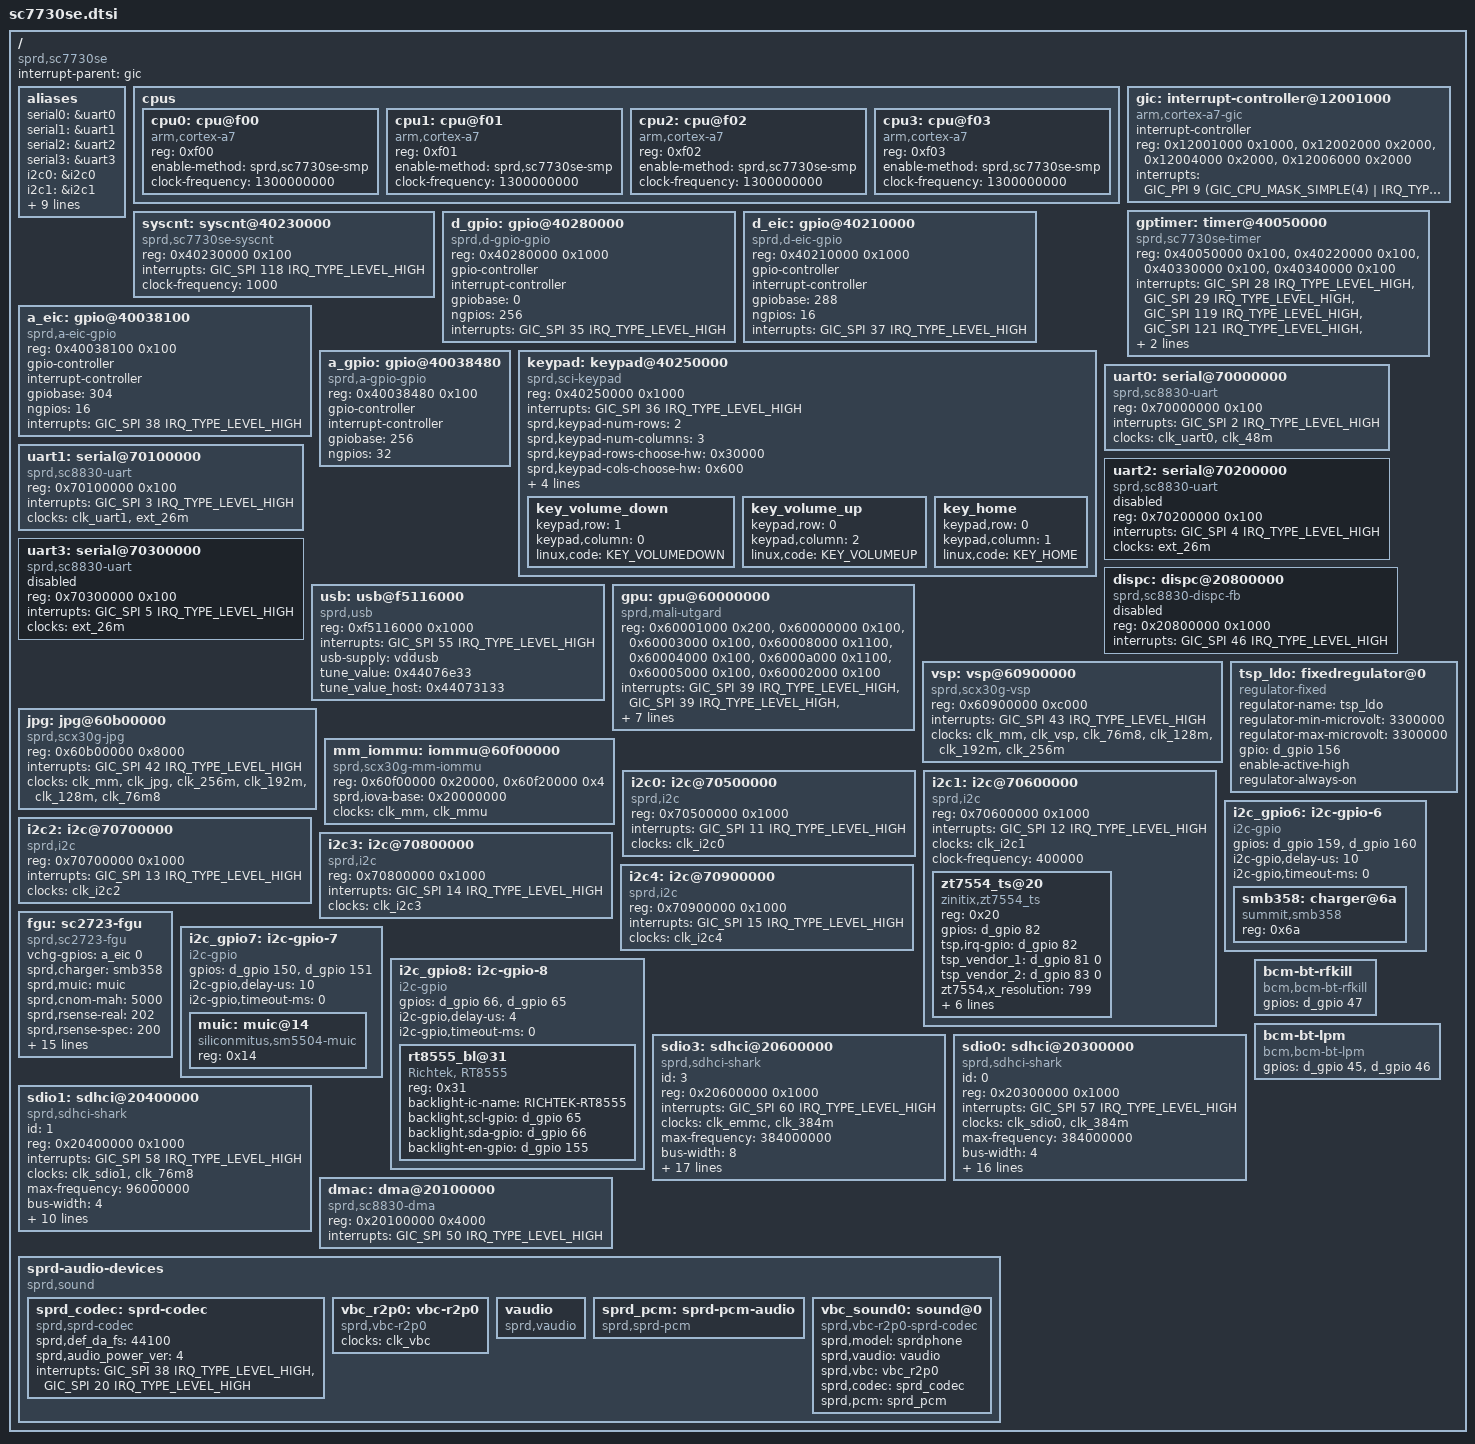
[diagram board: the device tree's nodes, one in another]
/*
 * Spreadtrum SC7730SE SoC Device Tree Include (SCX30G / SCX35 TShark2)
 *
 * Hardware map verified 1:1 against Samsung SM-T560 / SM-T561 3.10 kernel source
 * (sprd-scx35.dtsi, sprd-scx35_sc7730.dtsi, sprd-scx35_gtelwifi_rev11.dts,
 *  and sprd-scx35_gtel3g_rev11.dts).
 *
 * Peripherals are placed directly under '/' (matching sprd-scx35.dtsi) so
 * platform device sysfs paths (/devices/platform/sprd-sdhci.3) match Android's
 * fstab.sc8830 (/dev/block/platform/sprd-sdhci.3/by-name/SYSTEM).
 *
 * Licensed under the GPL-2.
 */

#include <dt-bindings/interrupt-controller/arm-gic.h>
#include <dt-bindings/interrupt-controller/irq.h>
#include <dt-bindings/gpio/gpio.h>
#include <dt-bindings/input/input.h>

#include "scx30g-clocks.dtsi"
#include "sc2723-regulators.dtsi"

/ {
	#address-cells = <1>;
	#size-cells = <1>;
	compatible = "sprd,sc7730se", "sprd,sc8830", "sprd,sp8830", "sprd,scx35";
	interrupt-parent = <&gic>;

	aliases {
		serial0 = &uart0;
		serial1 = &uart1;
		serial2 = &uart2;
		serial3 = &uart3;
		i2c0 = &i2c0;
		i2c1 = &i2c1;
		i2c2 = &i2c2;
		i2c3 = &i2c3;
		i2c4 = &i2c4;
		i2c6 = &i2c_gpio6;
		i2c7 = &i2c_gpio7;
		i2c8 = &i2c_gpio8;
		mmc0 = &sdio3;
		mmc1 = &sdio0;
		mmc2 = &sdio1;
	};

	cpus {
		#address-cells = <1>;
		#size-cells = <0>;

		cpu0: cpu@f00 {
			device_type = "cpu";
			compatible = "arm,cortex-a7";
			reg = <0xf00>;
			enable-method = "sprd,sc7730se-smp";
			clock-frequency = <1300000000>;
		};

		cpu1: cpu@f01 {
			device_type = "cpu";
			compatible = "arm,cortex-a7";
			reg = <0xf01>;
			enable-method = "sprd,sc7730se-smp";
			clock-frequency = <1300000000>;
		};

		cpu2: cpu@f02 {
			device_type = "cpu";
			compatible = "arm,cortex-a7";
			reg = <0xf02>;
			enable-method = "sprd,sc7730se-smp";
			clock-frequency = <1300000000>;
		};

		cpu3: cpu@f03 {
			device_type = "cpu";
			compatible = "arm,cortex-a7";
			reg = <0xf03>;
			enable-method = "sprd,sc7730se-smp";
			clock-frequency = <1300000000>;
		};
	};

	/*
	 * GIC-400 (Cortex-A7 MPCore has NO SCU MMIO block at 0x12000000!)
	 */
	gic: interrupt-controller@12001000 {
		compatible = "arm,cortex-a7-gic", "arm,cortex-a15-gic";
		#interrupt-cells = <3>;
		interrupt-controller;
		reg = <0x12001000 0x1000>,
		      <0x12002000 0x2000>,
		      <0x12004000 0x2000>,
		      <0x12006000 0x2000>;
		interrupts = <GIC_PPI 9 (GIC_CPU_MASK_SIMPLE(4) | IRQ_TYPE_LEVEL_HIGH)>;
	};

	/*
	 * Spreadtrum GPTIMERs (AON_TMR + AP_TMR0..2):
	 * - 0x40050000 (AON_TMR): CPU0 local timer (SPI 28) + 32768 Hz clocksource
	 * - 0x40220000 (AP_TMR0): CPU1 local timer (SPI 29) + bctimer (SPI 118)
	 * - 0x40330000 (AP_TMR1): CPU2 local timer (SPI 119)
	 * - 0x40340000 (AP_TMR2): CPU3 local timer (SPI 121)
	 */
	gptimer: timer@40050000 {
		compatible = "sprd,sc7730se-timer", "sprd,sc8830-timer", "sprd,scx35-timer";
		reg = <0x40050000 0x100>,
		      <0x40220000 0x100>,
		      <0x40330000 0x100>,
		      <0x40340000 0x100>;
		interrupts = <GIC_SPI 28 IRQ_TYPE_LEVEL_HIGH>,
			     <GIC_SPI 29 IRQ_TYPE_LEVEL_HIGH>,
			     <GIC_SPI 119 IRQ_TYPE_LEVEL_HIGH>,
			     <GIC_SPI 121 IRQ_TYPE_LEVEL_HIGH>,
			     <GIC_SPI 118 IRQ_TYPE_LEVEL_HIGH>;
		clock-frequency = <32768>;
	};

	/*
	 * Spreadtrum SYSCNT (0x40230000): 1000 Hz millisecond counter
	 */
	syscnt: syscnt@40230000 {
		compatible = "sprd,sc7730se-syscnt", "sprd,sc8830-syscnt";
		reg = <0x40230000 0x100>;
		interrupts = <GIC_SPI 118 IRQ_TYPE_LEVEL_HIGH>;
		clock-frequency = <1000>;
	};

	/*
	 * D-Die & A-Die GPIO and EIC Controllers (matching sprd-scx35.dtsi)
	 * - d_gpio: base 0, ngpios 256, GIC_SPI 35
	 * - a_gpio: base 256, ngpios 32
	 * - d_eic:  base 288, ngpios 16, GIC_SPI 37
	 * - a_eic:  base 304, ngpios 16, GIC_SPI 38 (ANA_INT)
	 */
	d_gpio: gpio@40280000 {
		compatible = "sprd,d-gpio-gpio";
		reg = <0x40280000 0x1000>;
		gpio-controller;
		#gpio-cells = <2>;
		interrupt-controller;
		#interrupt-cells = <2>;
		gpiobase = <0>;
		ngpios = <256>;
		interrupts = <GIC_SPI 35 IRQ_TYPE_LEVEL_HIGH>;
	};

	d_eic: gpio@40210000 {
		compatible = "sprd,d-eic-gpio";
		reg = <0x40210000 0x1000>;
		gpio-controller;
		#gpio-cells = <2>;
		interrupt-controller;
		#interrupt-cells = <2>;
		gpiobase = <288>;
		ngpios = <16>;
		interrupts = <GIC_SPI 37 IRQ_TYPE_LEVEL_HIGH>;
	};

	a_eic: gpio@40038100 {
		compatible = "sprd,a-eic-gpio";
		reg = <0x40038100 0x100>;
		gpio-controller;
		#gpio-cells = <2>;
		interrupt-controller;
		#interrupt-cells = <2>;
		gpiobase = <304>;
		ngpios = <16>;
		interrupts = <GIC_SPI 38 IRQ_TYPE_LEVEL_HIGH>;
	};

	a_gpio: gpio@40038480 {
		compatible = "sprd,a-gpio-gpio";
		reg = <0x40038480 0x100>;
		gpio-controller;
		#gpio-cells = <2>;
		interrupt-controller;
		#interrupt-cells = <2>;
		gpiobase = <256>;
		ngpios = <32>;
	};

	/*
	 * Spreadtrum Keypad Controller (0x40250000, GIC_SPI 36)
	 * Matching sprd-scx35_gtelwifi_rev11.dts / sprd-scx35_gtel3g_rev11.dts
	 */
	keypad: keypad@40250000 {
		compatible = "sprd,sci-keypad";
		reg = <0x40250000 0x1000>;
		interrupts = <GIC_SPI 36 IRQ_TYPE_LEVEL_HIGH>;
		sprd,keypad-num-rows = <2>;
		sprd,keypad-num-columns = <3>;
		sprd,keypad-rows-choose-hw = <0x30000>;
		sprd,keypad-cols-choose-hw = <0x600>;
		sprd,debounce_time = <5000>;
		linux,input-no-autorepeat;
		linux,input-wakeup;
		gpios = <&a_eic 2 0>, <&a_eic 10 0>;

		key_volume_down {
			keypad,row = <1>;
			keypad,column = <0>;
			linux,code = <KEY_VOLUMEDOWN>;
		};

		key_volume_up {
			keypad,row = <0>;
			keypad,column = <2>;
			linux,code = <KEY_VOLUMEUP>;
		};

		key_home {
			keypad,row = <0>;
			keypad,column = <1>;
			linux,code = <KEY_HOME>;
		};
	};

	/*
	 * Spreadtrum UARTs (0x70000000..0x70300000)
	 * uart0 is the Bluetooth HCI UART running at 48 MHz (3 Mbps baud).
	 */
	uart0: serial@70000000 {
		compatible = "sprd,sc8830-uart";
		reg = <0x70000000 0x100>;
		interrupts = <GIC_SPI 2 IRQ_TYPE_LEVEL_HIGH>;
		clocks = <&clk_uart0>, <&clk_48m>;
		status = "okay";
	};

	uart1: serial@70100000 {
		compatible = "sprd,sc8830-uart";
		reg = <0x70100000 0x100>;
		interrupts = <GIC_SPI 3 IRQ_TYPE_LEVEL_HIGH>;
		clocks = <&clk_uart1>, <&ext_26m>;
		status = "okay";
	};

	uart2: serial@70200000 {
		compatible = "sprd,sc8830-uart";
		reg = <0x70200000 0x100>;
		interrupts = <GIC_SPI 4 IRQ_TYPE_LEVEL_HIGH>;
		clocks = <&ext_26m>;
		status = "disabled";
	};

	uart3: serial@70300000 {
		compatible = "sprd,sc8830-uart";
		reg = <0x70300000 0x100>;
		interrupts = <GIC_SPI 5 IRQ_TYPE_LEVEL_HIGH>;
		clocks = <&ext_26m>;
		status = "disabled";
	};

	/*
	 * Mali-400 MP2 (Utgard r4p1).  All GP/PP/MMU interrupts share SPI 39.
	 * Register order/names follow the stock DT; the driver matches cores
	 * by address.
	 */
	/* Display controller (DISPC0), set up by the bootloader */
	dispc: dispc@20800000 {
		compatible = "sprd,sc8830-dispc-fb";
		reg = <0x20800000 0x1000>;
		interrupts = <GIC_SPI 46 IRQ_TYPE_LEVEL_HIGH>;
		status = "disabled";
	};

	/* DWC_otg 2.93a High-Speed USB 2.0 OTG Controller (0x20200000 mapped at 0xf5116000) */
	usb: usb@f5116000 {
		compatible = "sprd,usb";
		reg = <0xf5116000 0x1000>;
		interrupts = <GIC_SPI 55 IRQ_TYPE_LEVEL_HIGH>;
		usb-supply = <&vddusb>;
		tune_value = <0x44076e33>;
		tune_value_host = <0x44073133>;
		status = "okay";
	};

	gpu: gpu@60000000 {
		compatible = "sprd,mali-utgard";
		reg = <0x60001000 0x200>, <0x60000000 0x100>, <0x60003000 0x100>,
		      <0x60008000 0x1100>, <0x60004000 0x100>, <0x6000a000 0x1100>,
		      <0x60005000 0x100>, <0x60002000 0x100>;
		reg-names = "mali_l2", "mali_gp", "mali_gp_mmu", "mali_pp0",
			    "mali_pp0_mmu", "mali_pp1", "mali_pp1_mmu", "mali_pmu";
		interrupts = <GIC_SPI 39 IRQ_TYPE_LEVEL_HIGH>,
			     <GIC_SPI 39 IRQ_TYPE_LEVEL_HIGH>,
			     <GIC_SPI 39 IRQ_TYPE_LEVEL_HIGH>,
			     <GIC_SPI 39 IRQ_TYPE_LEVEL_HIGH>,
			     <GIC_SPI 39 IRQ_TYPE_LEVEL_HIGH>,
			     <GIC_SPI 39 IRQ_TYPE_LEVEL_HIGH>;
		interrupt-names = "mali_gp_irq", "mali_gp_mmu_irq",
				  "mali_pp0_irq", "mali_pp0_mmu_irq",
				  "mali_pp1_irq", "mali_pp1_mmu_irq";
		/* gpu_axi, then the clk_gpu mux inputs used for DVFS */
		clocks = <&clk_gpu_axi>, <&clk_384m>, <&clk_460m8>, <&clk_312m>,
			 <&clk_256m>, <&clk_153m6>;
		clock-names = "clk_gpu_axi", "clk_384m", "clk_460m8",
			      "clk_312m", "clk_256m", "clk_153m6";
		mali_pp_core_number = <2>;
	};

	/*
	 * Video (VSP) and JPEG codecs in the MM power domain, driven from
	 * userspace (OMX, camera HAL) through /dev/sprd_vsp and /dev/sprd_jpg.
	 * "levelN" is the codec clock input that frequency level N of the
	 * vendor ioctl ABI selects: mux order for the VSP, fastest first for
	 * the JPEG codec, as in the 3.10 drivers.
	 */
	vsp: vsp@60900000 {
		compatible = "sprd,scx30g-vsp";
		reg = <0x60900000 0xc000>;
		interrupts = <GIC_SPI 43 IRQ_TYPE_LEVEL_HIGH>;
		clocks = <&clk_mm>, <&clk_vsp>, <&clk_76m8>, <&clk_128m>,
			 <&clk_192m>, <&clk_256m>;
		clock-names = "clk_mm_i", "clk_vsp", "level0", "level1",
			      "level2", "level3";
	};

	jpg: jpg@60b00000 {
		compatible = "sprd,scx30g-jpg";
		reg = <0x60b00000 0x8000>;
		interrupts = <GIC_SPI 42 IRQ_TYPE_LEVEL_HIGH>;
		clocks = <&clk_mm>, <&clk_jpg>, <&clk_256m>, <&clk_192m>,
			 <&clk_128m>, <&clk_76m8>;
		clock-names = "clk_mm_i", "clk_jpg", "level0", "level1",
			      "level2", "level3";
	};

	/*
	 * IOMMU of the MM masters: page table SRAM (one entry per 4 KiB of
	 * the window) and control register, as on 3.10.
	 */
	mm_iommu: iommu@60f00000 {
		compatible = "sprd,scx30g-mm-iommu";
		reg = <0x60f00000 0x20000>, <0x60f20000 0x4>;
		reg-names = "pgt", "ctrl";
		sprd,iova-base = <0x20000000>;
		clocks = <&clk_mm>, <&clk_mmu>;
		clock-names = "clk_mm_i", "clk_mmu";
	};

	/*
	 * Zinitix ZT7554 3.3V LDO regulator (GPIO 156 active-high)
	 */
	tsp_ldo: fixedregulator@0 {
		compatible = "regulator-fixed";
		regulator-name = "tsp_ldo";
		regulator-min-microvolt = <3300000>;
		regulator-max-microvolt = <3300000>;
		gpio = <&d_gpio 156 0>;
		enable-active-high;
		regulator-always-on;
	};

	/*
	 * Spreadtrum Hardware I2C Controllers (0x70500000..0x70900000)
	 */
	i2c0: i2c@70500000 {
		compatible = "sprd,i2c", "sprd,sp8830-i2c";
		reg = <0x70500000 0x1000>;
		interrupts = <GIC_SPI 11 IRQ_TYPE_LEVEL_HIGH>;
		clocks = <&clk_i2c0>;
		#address-cells = <1>;
		#size-cells = <0>;
		status = "okay";
	};

	i2c1: i2c@70600000 {
		compatible = "sprd,i2c", "sprd,sp8830-i2c";
		reg = <0x70600000 0x1000>;
		interrupts = <GIC_SPI 12 IRQ_TYPE_LEVEL_HIGH>;
		clocks = <&clk_i2c1>;
		clock-frequency = <400000>;
		#address-cells = <1>;
		#size-cells = <0>;
		status = "okay";

		zt7554_ts@20 {
			compatible = "zinitix,zt7554_ts";
			reg = <0x20>;
			gpios = <&d_gpio 82 0>;
			tsp,irq-gpio = <&d_gpio 82 0>;
			tsp_vendor_1 = <&d_gpio 81 0>;
			tsp_vendor_2 = <&d_gpio 83 0>;
			zt7554,x_resolution = <799>;
			zt7554,y_resolution = <1279>;
			tsp,x_resolution = <800>;
			tsp,y_resolution = <1280>;
			tsp_vdd-supply = <&tsp_ldo>;
			zt7554,core_num = <4>;
			zt7554,model_name = "T560";
		};
	};

	i2c2: i2c@70700000 {
		compatible = "sprd,i2c", "sprd,sp8830-i2c";
		reg = <0x70700000 0x1000>;
		interrupts = <GIC_SPI 13 IRQ_TYPE_LEVEL_HIGH>;
		clocks = <&clk_i2c2>;
		#address-cells = <1>;
		#size-cells = <0>;
		status = "okay";
	};

	i2c3: i2c@70800000 {
		compatible = "sprd,i2c", "sprd,sp8830-i2c";
		reg = <0x70800000 0x1000>;
		interrupts = <GIC_SPI 14 IRQ_TYPE_LEVEL_HIGH>;
		clocks = <&clk_i2c3>;
		#address-cells = <1>;
		#size-cells = <0>;
		status = "okay";
	};

	i2c4: i2c@70900000 {
		compatible = "sprd,i2c", "sprd,sp8830-i2c";
		reg = <0x70900000 0x1000>;
		interrupts = <GIC_SPI 15 IRQ_TYPE_LEVEL_HIGH>;
		clocks = <&clk_i2c4>;
		#address-cells = <1>;
		#size-cells = <0>;
		status = "okay";
	};

	/*
	 * Bit-banged GPIO I2C buses from sprd-scx35_gtelwifi_rev11.dts:
	 * - i2c_gpio6: SMB358 charger (SDA=GPIO159, SCL=GPIO160)
	 * - i2c_gpio7: SM5504 MUIC (SDA=GPIO150, SCL=GPIO151)
	 * - i2c_gpio8: Richtek RT8555 Backlight (SDA=GPIO66, SCL=GPIO65, EN=GPIO155)
	 */
	i2c_gpio6: i2c-gpio-6 {
		compatible = "i2c-gpio";
		gpios = <&d_gpio 159 0 /* sda */
			 &d_gpio 160 0 /* scl */>;
		i2c-gpio,delay-us = <10>;
		i2c-gpio,timeout-ms = <0>;
		#address-cells = <1>;
		#size-cells = <0>;
		status = "okay";

		/* set up by the SC2723 FGU driver for each charger attach */
		smb358: charger@6a {
			compatible = "summit,smb358";
			reg = <0x6a>;
		};
	};

	/*
	 * SC2723 fuel gauge. Battery data from the vendor 3.10
	 * sprd-scx35_gtelwifi/gtel3g DTs (5000 mAh pack, identical on all
	 * revisions); the NTC table is Samsung's sec_battery one.
	 */
	fgu: sc2723-fgu {
		compatible = "sprd,sc2723-fgu";
		vchg-gpios = <&a_eic 0 GPIO_ACTIVE_HIGH>;
		sprd,charger = <&smb358>;
		sprd,muic = <&muic>;
		sprd,cnom-mah = <5000>;
		sprd,rsense-real = <202>;
		sprd,rsense-spec = <200>;
		sprd,rint-mohm = <220>;
		sprd,relax-current-ma = <50>;
		sprd,alm-vbat-mv = <3500>;
		sprd,soft-uvlo-mv = <3050>;
		sprd,temp-adc-channel = <1>;
		/* OCV in mV, capacity in % */
		sprd,ocv-table = <4320 100>, <4262 95>, <4205 90>, <4152 85>,
				 <4101 80>, <4055 75>, <4006 70>, <3968 65>,
				 <3923 60>, <3880 55>, <3849 50>, <3824 45>,
				 <3806 40>, <3790 35>, <3778 30>, <3770 25>,
				 <3761 20>, <3744 15>, <3711 10>, <3690 5>,
				 <3400 0>;
		/* AUXADC raw value, temperature in 0.1 degC */
		sprd,temp-table = <653 700>, <889 600>, <963 580>, <1093 530>,
				  <1177 500>, <1307 460>, <1334 450>, <1549 400>,
				  <1940 300>, <2392 200>, <2727 100>, <2900 50>,
				  <3040 0>, <3210 (-50)>, <3360 (-100)>,
				  <3537 (-200)>;
		status = "okay";
	};

	i2c_gpio7: i2c-gpio-7 {
		compatible = "i2c-gpio";
		gpios = <&d_gpio 150 0 /* sda */
			 &d_gpio 151 0 /* scl */>;
		i2c-gpio,delay-us = <10>;
		i2c-gpio,timeout-ms = <0>;
		#address-cells = <1>;
		#size-cells = <0>;
		status = "okay";

		/* charger type, only read by the SC2723 FGU driver */
		muic: muic@14 {
			compatible = "siliconmitus,sm5504-muic";
			reg = <0x14>;
		};
	};

	i2c_gpio8: i2c-gpio-8 {
		compatible = "i2c-gpio";
		gpios = <&d_gpio 66 0 /* sda */
			 &d_gpio 65 0 /* scl */>;
		i2c-gpio,delay-us = <4>;
		i2c-gpio,timeout-ms = <0>;
		#address-cells = <1>;
		#size-cells = <0>;
		status = "okay";

		rt8555_bl@31 {
			compatible = "Richtek, RT8555";
			reg = <0x31>;
			backlight-ic-name = "RICHTEK-RT8555";
			backlight,scl-gpio = <&d_gpio 65 0>;
			backlight,sda-gpio = <&d_gpio 66 0>;
			backlight-en-gpio = <&d_gpio 155 GPIO_ACTIVE_HIGH>;
		};
	};

	/*
	 * Spreadtrum SDHCI Controllers (eMMC, SD, Wi-Fi SDIO)
	 * Placed directly under '/' so devpath is /devices/platform/sprd-sdhci.{0,1,3}
	 */
	sdio3: sdhci@20600000 {
		compatible = "sprd,sdhci-shark";
		id = <3>;
		reg = <0x20600000 0x1000>;
		interrupts = <GIC_SPI 60 IRQ_TYPE_LEVEL_HIGH>;
		clocks = <&clk_emmc>, <&clk_384m>;
		max-frequency = <384000000>;
		bus-width = <8>;
		enb-reg = <0x20d00000>;
		enb-bit = <0x800>;
		rst-reg = <0x20d00004>;
		rst-bit = <0x4000>;
		write-delay = <0x08>;
		read-pos-delay = <0x04>;
		read-neg-delay = <0x04>;
		host-caps-mask = <0x03000000>;
		sdhci-cap-1v8-ddr;
		sdhci-cap2-hc-erase-sz;
		sdhci-cap2-cache-ctrl;
		sdhci-cap2-poweroff-notify;
		sdhci-cap2-no-sleep-cmd;
		sdhci-cap2-power-always-on;
		non-removable;
		keep-power = <0>;
		runtime = <1>;
		status = "okay";
	};

	sdio0: sdhci@20300000 {
		compatible = "sprd,sdhci-shark";
		id = <0>;
		reg = <0x20300000 0x1000>;
		interrupts = <GIC_SPI 57 IRQ_TYPE_LEVEL_HIGH>;
		clocks = <&clk_sdio0>, <&clk_384m>;
		max-frequency = <384000000>;
		bus-width = <4>;
		enb-reg = <0x20d00000>;
		enb-bit = <0x100>;
		rst-reg = <0x20d00004>;
		rst-bit = <0x800>;
		write-delay = <0x08>;
		read-pos-delay = <0x08>;
		read-neg-delay = <0x08>;
		host-caps-mask = <0x05000000>;
		vdd-vmmc = "vddsdcore";
		vdd-vqmmc = "vddsdcore";
		vqmmc-voltage-level = <3000000>;
		cd-gpios = <&d_gpio 71 GPIO_ACTIVE_LOW>;
		sdhci-cap2-hc-erase-sz;
		sdhci-cap2-cache-ctrl;
		keep-power = <0>;
		runtime = <1>;
		status = "okay";
	};

	sdio1: sdhci@20400000 {
		compatible = "sprd,sdhci-shark";
		id = <1>;
		reg = <0x20400000 0x1000>;
		interrupts = <GIC_SPI 58 IRQ_TYPE_LEVEL_HIGH>;
		clocks = <&clk_sdio1>, <&clk_76m8>;
		max-frequency = <96000000>;
		bus-width = <4>;
		enb-reg = <0x20d00000>;
		enb-bit = <0x200>;
		rst-reg = <0x20d00004>;
		rst-bit = <0x1000>;
		write-delay = <0x03>;
		read-pos-delay = <0x05>;
		read-neg-delay = <0x05>;
		non-removable;
		keep-power = <1>;
		runtime = <1>;
		status = "okay";
	};

	bcm-bt-rfkill {
		compatible = "bcm,bcm-bt-rfkill";
		gpios = <&d_gpio 47 0>;
	};

	bcm-bt-lpm {
		compatible = "bcm,bcm-bt-lpm";
		gpios = <&d_gpio 45 0
			 &d_gpio 46 0>;
	};

	dmac: dma@20100000 {
		compatible = "sprd,sc8830-dma", "sprd,sprd-dma";
		reg = <0x20100000 0x4000>;
		interrupts = <GIC_SPI 50 IRQ_TYPE_LEVEL_HIGH>;
	};

	sprd-audio-devices {
		compatible = "sprd,sound", "simple-bus";
		#address-cells = <1>;
		#size-cells = <1>;

		sprd_codec: sprd-codec {
			compatible = "sprd,sprd-codec";
			status = "okay";
			sprd,def_da_fs = <44100>;
			sprd,audio_power_ver = <4>;
			interrupts = <GIC_SPI 38 IRQ_TYPE_LEVEL_HIGH>,
				     <GIC_SPI 20 IRQ_TYPE_LEVEL_HIGH>;
		};

		vbc_r2p0: vbc-r2p0 {
			compatible = "sprd,vbc-r2p0";
			clocks = <&clk_vbc>;
			clock-names = "clk_vbc";
			status = "okay";
		};

		vaudio: vaudio {
			compatible = "sprd,vaudio";
			status = "okay";
		};

		sprd_pcm: sprd-pcm-audio {
			compatible = "sprd,sprd-pcm";
			status = "okay";
		};

		vbc_sound0: sound@0 {
			compatible = "sprd,vbc-r2p0-sprd-codec";
			sprd,model = "sprdphone";
			sprd,vaudio = <&vaudio>;
			sprd,vbc = <&vbc_r2p0>;
			sprd,codec = <&sprd_codec>;
			sprd,pcm = <&sprd_pcm>;
			status = "okay";
		};
	};
};
